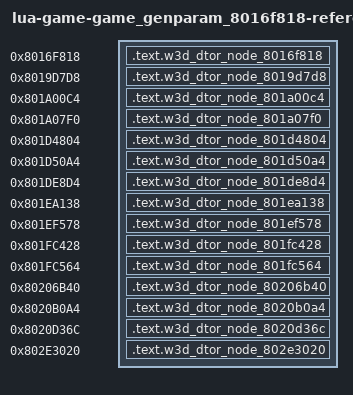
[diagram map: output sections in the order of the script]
/* Generated reference-only placements. All bodies are source-built. */
OUTPUT_FORMAT("elf32-powerpc")
OUTPUT_ARCH(powerpc)
ENTRY(w3d_dtor_node_8016f818)
_SDA_BASE_ = 0x804b2540;
_SDA2_BASE_ = 0x804c2540;
fn_801e828c = 0x801e828c;
fn_801ea740 = 0x801ea740;
fn_801ef5cc = 0x801ef5cc;
fn_801fe1f8 = 0x801fe1f8;
fn_80210990 = 0x80210990;
w3d_vtable_80411590 = 0x80411590;
w3d_vtable_80411ac0 = 0x80411ac0;
w3d_vtable_80411fc0 = 0x80411fc0;
w3d_vtable_80413730 = 0x80413730;
w3d_vtable_80413920 = 0x80413920;
w3d_vtable_80416610 = 0x80416610;
w3d_vtable_80416678 = 0x80416678;
w3d_vtable_80416b50 = 0x80416b50;
w3d_vtable_804181c0 = 0x804181c0;
w3d_vtable_804182d0 = 0x804182d0;
w3d_vtable_80418328 = 0x80418328;
w3d_vtable_8041cb40 = 0x8041cb40;
SECTIONS {
  .text.w3d_dtor_node_8016f818 0x8016f818 : { *(.text.w3d_dtor_node_8016f818) }
  .text.w3d_dtor_node_8019d7d8 0x8019d7d8 : { *(.text.w3d_dtor_node_8019d7d8) }
  .text.w3d_dtor_node_801a00c4 0x801a00c4 : { *(.text.w3d_dtor_node_801a00c4) }
  .text.w3d_dtor_node_801a07f0 0x801a07f0 : { *(.text.w3d_dtor_node_801a07f0) }
  .text.w3d_dtor_node_801d4804 0x801d4804 : { *(.text.w3d_dtor_node_801d4804) }
  .text.w3d_dtor_node_801d50a4 0x801d50a4 : { *(.text.w3d_dtor_node_801d50a4) }
  .text.w3d_dtor_node_801de8d4 0x801de8d4 : { *(.text.w3d_dtor_node_801de8d4) }
  .text.w3d_dtor_node_801ea138 0x801ea138 : { *(.text.w3d_dtor_node_801ea138) }
  .text.w3d_dtor_node_801ef578 0x801ef578 : { *(.text.w3d_dtor_node_801ef578) }
  .text.w3d_dtor_node_801fc428 0x801fc428 : { *(.text.w3d_dtor_node_801fc428) }
  .text.w3d_dtor_node_801fc564 0x801fc564 : { *(.text.w3d_dtor_node_801fc564) }
  .text.w3d_dtor_node_80206b40 0x80206b40 : { *(.text.w3d_dtor_node_80206b40) }
  .text.w3d_dtor_node_8020b0a4 0x8020b0a4 : { *(.text.w3d_dtor_node_8020b0a4) }
  .text.w3d_dtor_node_8020d36c 0x8020d36c : { *(.text.w3d_dtor_node_8020d36c) }
  .text.w3d_dtor_node_802e3020 0x802e3020 : { *(.text.w3d_dtor_node_802e3020) }
  /DISCARD/ : { *(.text*) *(.rodata*) *(.data*) *(.bss*) *(.sdata*) *(.sbss*) *(.comment) }
}
